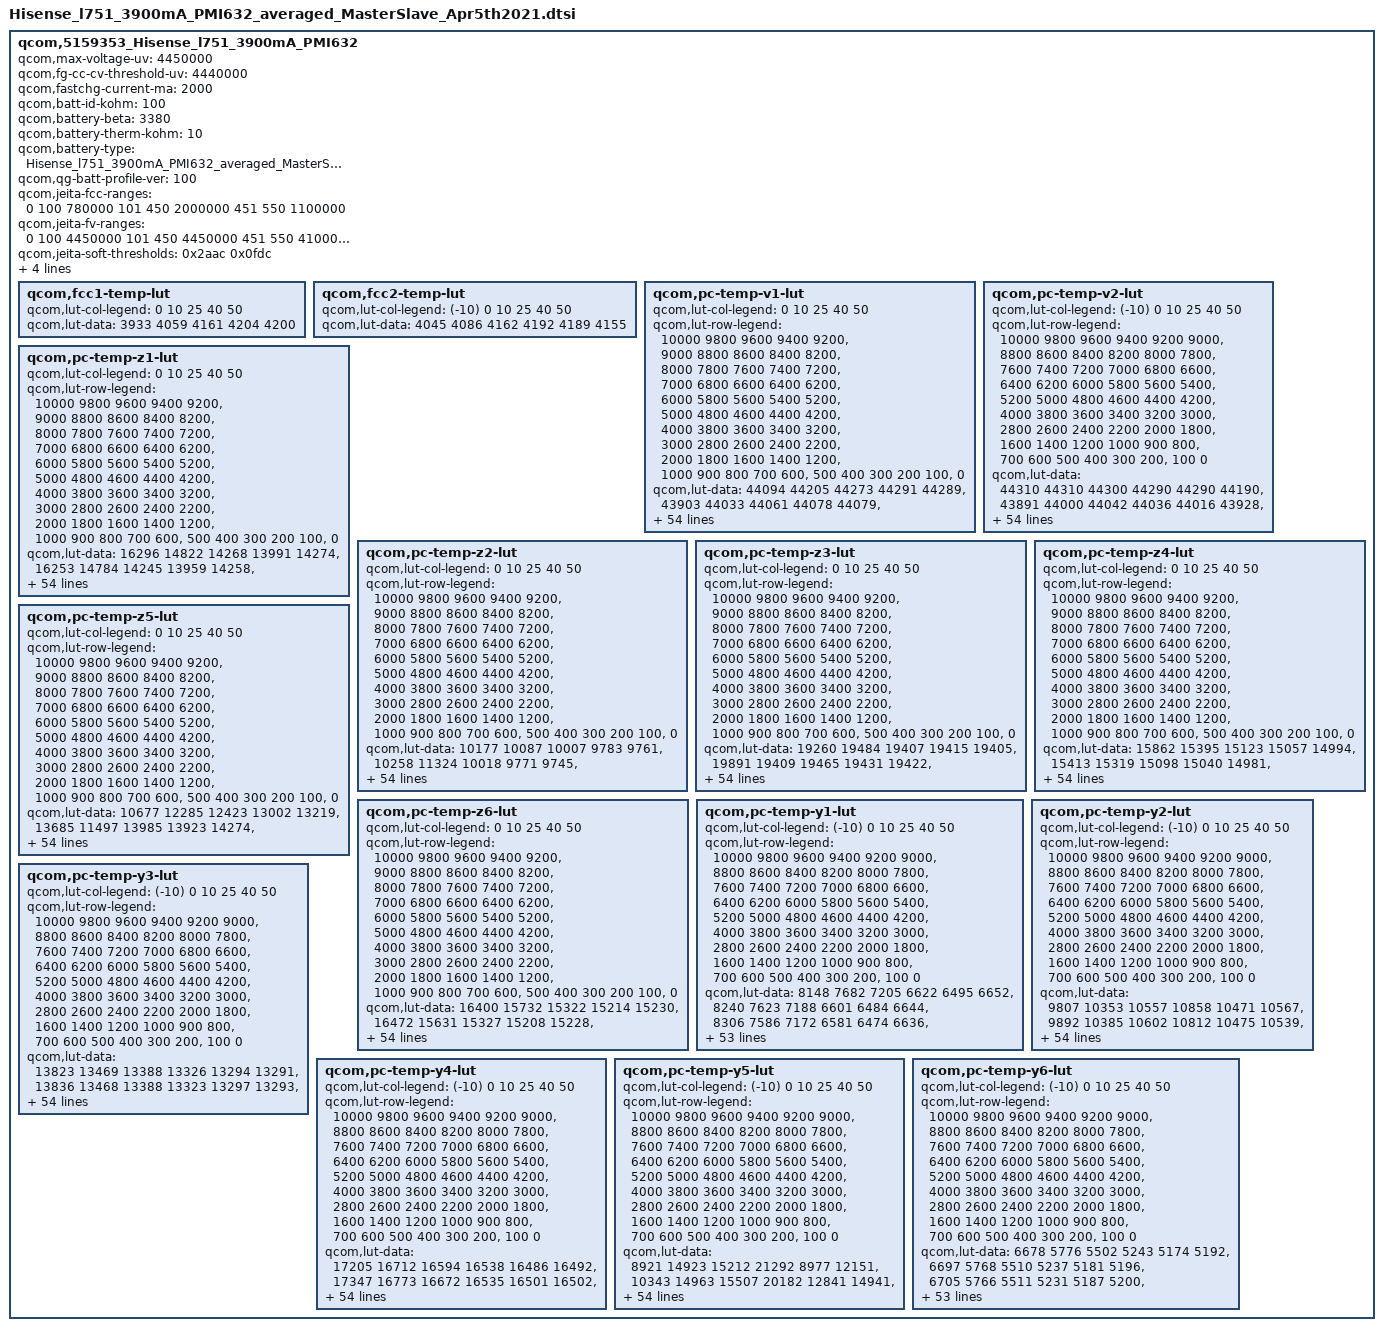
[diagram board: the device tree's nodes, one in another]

qcom,5159353_Hisense_l751_3900mA_PMI632 {
    /* 5159353_Hisense_l751_3900mA_PMI632_averaged_MasterSlave_Apr5th2021 */
    qcom,max-voltage-uv = <4450000>;
    qcom,fg-cc-cv-threshold-uv = <4440000>;
	qcom,fastchg-current-ma = <2000>;
	qcom,batt-id-kohm = <100>;
	qcom,battery-beta = <3380>;
	qcom,battery-therm-kohm = <10>;
    qcom,battery-type = "Hisense_l751_3900mA_PMI632_averaged_MasterSlave_Apr5th2021";
	qcom,qg-batt-profile-ver = <100>;

	qcom,jeita-fcc-ranges = <0  100  780000
				101 450  2000000
				451 550  1100000>;

	qcom,jeita-fv-ranges =  <0  100  4450000
				 101 450  4450000
				 451 550  4100000>;
	/* COOL = 10 DegC, WARM = 45 DegC */
	qcom,jeita-soft-thresholds = <0x2aac 0x0fdc>;
	/* COLD = 0 DegC, HOT = 53 DegC */
	qcom,jeita-hard-thresholds = <0x36b9 0x0ca0>;
	/* COOL hys = 13 degC, WARM hys = 42 degC */
	qcom,jeita-soft-hys-thresholds = <0x2767 0x1149>;
	qcom,jeita-soft-fcc-ua = <780000 1100000>;
	qcom,jeita-soft-fv-uv = <4450000 4100000>;

	qcom,fcc1-temp-lut {
		qcom,lut-col-legend = <0 10 25 40 50>;
		qcom,lut-data = <3933 4059 4161 4204 4200>;
	};

	qcom,fcc2-temp-lut {
		qcom,lut-col-legend = <(-10) 0 10 25 40 50>;
		qcom,lut-data = <4045 4086 4162 4192 4189 4155>;
	};

	qcom,pc-temp-v1-lut {
		qcom,lut-col-legend = <0 10 25 40 50>;
		qcom,lut-row-legend = <10000 9800 9600 9400 9200>,
			<9000 8800 8600 8400 8200>,
			<8000 7800 7600 7400 7200>,
			<7000 6800 6600 6400 6200>,
			<6000 5800 5600 5400 5200>,
			<5000 4800 4600 4400 4200>,
			<4000 3800 3600 3400 3200>,
			<3000 2800 2600 2400 2200>,
			<2000 1800 1600 1400 1200>,
			<1000 900 800 700 600>,
			<500 400 300 200 100>,
			<0>;
		qcom,lut-data = <44094 44205 44273 44291 44289>,
			<43903 44033 44061 44078 44079>,
			<43671 43842 43845 43865 43876>,
			<43436 43624 43630 43659 43668>,
			<43200 43391 43405 43437 43456>,
			<42959 43146 43172 43208 43228>,
			<42717 42888 42930 42973 42993>,
			<42473 42636 42677 42729 42749>,
			<42234 42388 42427 42481 42501>,
			<42000 42144 42177 42232 42256>,
			<41770 41906 41934 41982 42012>,
			<41545 41672 41700 41738 41770>,
			<41324 41443 41472 41497 41529>,
			<41111 41217 41244 41264 41293>,
			<40904 41002 41018 41040 41064>,
			<40701 40802 40802 40824 40841>,
			<40495 40605 40596 40612 40627>,
			<40291 40404 40397 40409 40422>,
			<40107 40202 40207 40223 40234>,
			<39940 40015 40020 40049 40058>,
			<39778 39853 39827 39862 39871>,
			<39616 39672 39630 39654 39668>,
			<39454 39412 39420 39438 39455>,
			<39270 39133 39174 39199 39211>,
			<39046 38951 38960 38972 38980>,
			<38849 38819 38825 38833 38840>,
			<38710 38711 38721 38738 38742>,
			<38597 38620 38621 38645 38644>,
			<38516 38541 38530 38552 38543>,
			<38455 38464 38444 38464 38448>,
			<38404 38393 38361 38385 38364>,
			<38354 38330 38286 38310 38287>,
			<38309 38275 38224 38242 38217>,
			<38270 38225 38168 38177 38152>,
			<38237 38181 38116 38114 38084>,
			<38205 38139 38067 38051 38011>,
			<38175 38099 38019 37988 37939>,
			<38143 38062 37975 37933 37875>,
			<38098 38014 37925 37873 37806>,
			<38032 37943 37852 37787 37713>,
			<37950 37851 37754 37674 37594>,
			<37833 37742 37642 37553 37469>,
			<37700 37609 37508 37426 37337>,
			<37578 37456 37355 37276 37185>,
			<37424 37298 37203 37126 37043>,
			<37274 37171 37104 37047 36974>,
			<37223 37135 37071 37010 36941>,
			<37177 37105 37045 36983 36917>,
			<37139 37078 37026 36960 36892>,
			<37105 37046 36992 36916 36842>,
			<37068 36999 36823 36710 36620>,
			<36985 36743 36420 36292 36194>,
			<36662 36289 35848 35730 35632>,
			<36106 35573 35063 34967 34866>,
			<35184 34476 33838 33810 33686>,
			<30000 30000 30000 30000 30000>;
	};

	qcom,pc-temp-v2-lut {
		qcom,lut-col-legend = <(-10) 0 10 25 40 50>;
		qcom,lut-row-legend = <10000 9800 9600 9400 9200 9000>,
			<8800 8600 8400 8200 8000 7800>,
			<7600 7400 7200 7000 6800 6600>,
			<6400 6200 6000 5800 5600 5400>,
			<5200 5000 4800 4600 4400 4200>,
			<4000 3800 3600 3400 3200 3000>,
			<2800 2600 2400 2200 2000 1800>,
			<1600 1400 1200 1000 900 800>,
			<700 600 500 400 300 200>,
			<100 0>;
		qcom,lut-data = <44310 44310 44300 44290 44290 44190>,
			<43891 44000 44042 44036 44016 43928>,
			<43526 43720 43802 43792 43759 43680>,
			<43226 43473 43585 43562 43528 43452>,
			<42978 43256 43387 43343 43314 43239>,
			<42728 43035 43172 43113 43086 43014>,
			<42460 42807 42933 42869 42838 42770>,
			<42191 42573 42688 42621 42586 42522>,
			<41923 42327 42442 42370 42336 42275>,
			<41659 42074 42193 42117 42086 42027>,
			<41453 41831 41949 41868 41837 41782>,
			<41306 41597 41708 41622 41591 41539>,
			<41151 41369 41470 41381 41350 41300>,
			<40944 41145 41232 41146 41115 41066>,
			<40698 40929 41002 40917 40887 40838>,
			<40401 40734 40785 40691 40665 40619>,
			<40027 40554 40574 40473 40450 40407>,
			<39709 40336 40359 40268 40246 40207>,
			<39489 40041 40141 40075 40052 40019>,
			<39293 39747 39911 39875 39861 39828>,
			<39064 39509 39654 39668 39677 39634>,
			<38821 39295 39406 39452 39478 39430>,
			<38626 39097 39188 39203 39226 39193>,
			<38470 38913 38989 38963 38973 38947>,
			<38349 38745 38816 38786 38795 38765>,
			<38267 38592 38664 38641 38653 38626>,
			<38204 38451 38528 38512 38526 38503>,
			<38144 38307 38406 38398 38411 38390>,
			<38089 38169 38295 38295 38307 38287>,
			<38035 38070 38189 38201 38214 38193>,
			<37982 38000 38091 38116 38130 38106>,
			<37928 37943 38005 38038 38056 38028>,
			<37873 37895 37928 37964 37990 37959>,
			<37816 37852 37864 37896 37919 37887>,
			<37758 37803 37814 37834 37842 37807>,
			<37698 37747 37769 37771 37759 37719>,
			<37635 37688 37721 37707 37666 37617>,
			<37568 37629 37671 37639 37570 37501>,
			<37498 37564 37610 37563 37484 37401>,
			<37424 37490 37536 37480 37400 37314>,
			<37344 37404 37444 37391 37310 37232>,
			<37255 37304 37328 37293 37219 37136>,
			<37158 37188 37189 37163 37102 36967>,
			<37059 37056 37051 37018 36950 36861>,
			<36957 36920 36920 36918 36863 36794>,
			<36854 36794 36845 36874 36831 36768>,
			<36807 36749 36804 36859 36819 36752>,
			<36765 36707 36779 36839 36802 36725>,
			<36729 36659 36718 36804 36760 36651>,
			<36690 36599 36641 36698 36622 36334>,
			<36655 36500 36404 36336 36232 35842>,
			<36592 36324 35945 35781 35676 35188>,
			<36461 35951 35247 35036 34939 34298>,
			<36163 35264 34331 34002 33943 33249>,
			<35495 34279 33175 32807 32804 32450>,
			<34477 33023 31869 28509 28709 29554>;
	};

	qcom,pc-temp-z1-lut {
		qcom,lut-col-legend = <0 10 25 40 50>;
		qcom,lut-row-legend = <10000 9800 9600 9400 9200>,
			<9000 8800 8600 8400 8200>,
			<8000 7800 7600 7400 7200>,
			<7000 6800 6600 6400 6200>,
			<6000 5800 5600 5400 5200>,
			<5000 4800 4600 4400 4200>,
			<4000 3800 3600 3400 3200>,
			<3000 2800 2600 2400 2200>,
			<2000 1800 1600 1400 1200>,
			<1000 900 800 700 600>,
			<500 400 300 200 100>,
			<0>;
		qcom,lut-data = <16296 14822 14268 13991 14274>,
			<16253 14784 14245 13959 14258>,
			<16252 14771 14224 13935 14239>,
			<16249 14751 14182 13917 14231>,
			<16223 14735 14154 13893 14224>,
			<16188 14710 14129 13876 14215>,
			<16164 14682 14104 13860 14209>,
			<16141 14657 14080 13845 14204>,
			<16117 14636 14064 13831 14201>,
			<16087 14616 14053 13821 14201>,
			<16069 14593 14044 13813 14201>,
			<16069 14571 14032 13809 14202>,
			<16069 14559 14021 13806 14206>,
			<16064 14550 14015 13804 14208>,
			<16011 14543 14010 13803 14209>,
			<15959 14535 14009 13802 14209>,
			<15943 14531 14009 13800 14211>,
			<15934 14538 14008 13799 14214>,
			<15930 14556 14006 13800 14216>,
			<15928 14560 14002 13802 14218>,
			<15927 14550 14001 13805 14220>,
			<15935 14544 14004 13807 14223>,
			<15953 14548 14008 13809 14225>,
			<15968 14557 14016 13812 14228>,
			<15979 14566 14023 13816 14233>,
			<15990 14577 14024 13820 14237>,
			<15999 14585 14025 13826 14243>,
			<16007 14590 14026 13832 14248>,
			<16021 14595 14028 13838 14253>,
			<16049 14603 14030 13843 14258>,
			<16072 14613 14037 13849 14263>,
			<16083 14628 14047 13856 14268>,
			<16091 14659 14061 13864 14275>,
			<16090 14678 14077 13874 14283>,
			<16075 14676 14085 13882 14292>,
			<16064 14672 14088 13889 14299>,
			<16074 14674 14093 13895 14307>,
			<16096 14687 14103 13903 14315>,
			<16119 14704 14114 13911 14321>,
			<16145 14724 14121 13918 14328>,
			<16171 14748 14128 13925 14333>,
			<16194 14781 14138 13934 14337>,
			<16220 14813 14155 13944 14341>,
			<16257 14805 14168 13953 14345>,
			<16282 14803 14179 13961 14348>,
			<16298 14837 14190 13965 14351>,
			<16304 14839 14194 13965 14351>,
			<16304 14854 14212 13969 14354>,
			<16301 14849 14214 13974 14360>,
			<16304 14862 14218 13984 14367>,
			<16342 14886 14237 14003 14378>,
			<16351 15046 14275 14014 14387>,
			<16378 15355 14309 14028 14399>,
			<16417 15325 14317 14052 14420>,
			<16417 15325 14317 14052 14420>,
			<16417 15325 14317 14052 14420>;
	};

	qcom,pc-temp-z2-lut {
		qcom,lut-col-legend = <0 10 25 40 50>;
		qcom,lut-row-legend = <10000 9800 9600 9400 9200>,
			<9000 8800 8600 8400 8200>,
			<8000 7800 7600 7400 7200>,
			<7000 6800 6600 6400 6200>,
			<6000 5800 5600 5400 5200>,
			<5000 4800 4600 4400 4200>,
			<4000 3800 3600 3400 3200>,
			<3000 2800 2600 2400 2200>,
			<2000 1800 1600 1400 1200>,
			<1000 900 800 700 600>,
			<500 400 300 200 100>,
			<0>;
		qcom,lut-data = <10177 10087 10007 9783 9761>,
			<10258 11324 10018 9771 9745>,
			<10036 11209 10047 9816 9751>,
			<9936 10961 10050 9778 9770>,
			<9918 10612 10032 9880 9832>,
			<9905 10316 10002 9879 9886>,
			<9892 10043 9983 9875 9901>,
			<9881 9968 9968 9847 9888>,
			<9875 9955 9953 9822 9873>,
			<9870 9947 9935 9818 9860>,
			<9868 9940 9926 9816 9851>,
			<9869 9935 10148 9820 9852>,
			<9872 9937 10481 9834 9859>,
			<9876 9947 10552 9838 9867>,
			<9885 9972 10572 9818 9880>,
			<9896 10136 10594 9801 9887>,
			<9905 10294 10625 9810 9885>,
			<9915 10229 10642 9824 9880>,
			<9930 10059 10397 9810 9856>,
			<9953 10011 10010 9753 9798>,
			<9973 10019 9961 9737 9784>,
			<9983 10028 9980 9808 9856>,
			<9989 10033 10000 9905 9952>,
			<9994 10037 10021 10011 10064>,
			<9996 10037 10033 10103 10160>,
			<9999 10031 10021 10086 10150>,
			<10005 10028 9997 9996 10080>,
			<10013 10027 9988 9954 10016>,
			<10017 10027 9984 9947 9961>,
			<10018 10028 9980 9938 9908>,
			<10020 10030 9977 9898 9852>,
			<10024 10032 9974 9842 9801>,
			<10030 10034 9970 9807 9759>,
			<10036 10037 9966 9780 9723>,
			<10042 10045 9968 9773 9715>,
			<10048 10057 9983 9778 9731>,
			<10056 10067 10001 9784 9754>,
			<10065 10077 10020 9793 9792>,
			<10077 10087 10038 9806 9835>,
			<10092 10102 10053 9841 9858>,
			<10106 10114 10065 9905 9872>,
			<10112 10115 10071 9926 9896>,
			<10137 10115 10074 9927 9939>,
			<17121 10121 10075 9934 9969>,
			<19781 10165 10078 9944 9977>,
			<19355 10238 10102 9853 9851>,
			<18978 10262 10105 9850 9844>,
			<19289 10315 10102 9852 9846>,
			<19818 10470 10101 9865 9863>,
			<20094 10287 10134 9894 9889>,
			<18666 11110 10142 9874 9863>,
			<18118 10773 10109 9794 9763>,
			<17012 10835 10062 9743 9708>,
			<14924 10113 10005 9709 9666>,
			<14924 10113 10005 9709 9666>,
			<14924 10113 10005 9709 9666>;
	};

	qcom,pc-temp-z3-lut {
		qcom,lut-col-legend = <0 10 25 40 50>;
		qcom,lut-row-legend = <10000 9800 9600 9400 9200>,
			<9000 8800 8600 8400 8200>,
			<8000 7800 7600 7400 7200>,
			<7000 6800 6600 6400 6200>,
			<6000 5800 5600 5400 5200>,
			<5000 4800 4600 4400 4200>,
			<4000 3800 3600 3400 3200>,
			<3000 2800 2600 2400 2200>,
			<2000 1800 1600 1400 1200>,
			<1000 900 800 700 600>,
			<500 400 300 200 100>,
			<0>;
		qcom,lut-data = <19260 19484 19407 19415 19405>,
			<19891 19409 19465 19431 19422>,
			<19848 19466 19493 19449 19416>,
			<19834 19545 19532 19447 19434>,
			<19853 19611 19535 19492 19462>,
			<19875 19647 19537 19499 19473>,
			<19885 19672 19543 19503 19482>,
			<19891 19682 19553 19506 19491>,
			<19892 19687 19555 19510 19495>,
			<19877 19689 19554 19514 19495>,
			<19860 19684 19552 19519 19495>,
			<19849 19674 19563 19518 19493>,
			<19841 19666 19579 19512 19489>,
			<19831 19657 19580 19506 19485>,
			<19819 19654 19574 19497 19481>,
			<19811 19671 19569 19490 19476>,
			<19811 19688 19565 19485 19472>,
			<19812 19676 19560 19481 19467>,
			<19809 19643 19538 19473 19458>,
			<19788 19632 19510 19460 19447>,
			<19771 19630 19508 19455 19443>,
			<19775 19629 19512 19461 19445>,
			<19786 19644 19517 19468 19447>,
			<19799 19668 19522 19481 19456>,
			<19819 19670 19524 19494 19469>,
			<19832 19662 19519 19493 19477>,
			<19831 19655 19509 19488 19482>,
			<19828 19649 19508 19488 19490>,
			<19824 19646 19512 19504 19505>,
			<19815 19647 19518 19515 19514>,
			<19805 19650 19529 19514 19507>,
			<19798 19651 19537 19510 19493>,
			<19791 19648 19534 19503 19479>,
			<19785 19645 19525 19493 19464>,
			<19778 19643 19519 19482 19451>,
			<19772 19642 19514 19471 19440>,
			<19767 19640 19509 19460 19430>,
			<19761 19637 19501 19446 19418>,
			<19753 19633 19494 19434 19408>,
			<19743 19627 19490 19435 19409>,
			<19734 19620 19487 19440 19414>,
			<19731 19612 19483 19442 19421>,
			<19725 19604 19478 19442 19429>,
			<19368 19594 19476 19446 19437>,
			<19256 19573 19474 19451 19441>,
			<19256 19546 19455 19423 19420>,
			<19256 19523 19450 19418 19414>,
			<19256 19498 19448 19411 19394>,
			<19256 19449 19432 19402 19382>,
			<19256 19497 19412 19390 19380>,
			<19256 19323 19440 19413 19398>,
			<19256 19316 19455 19446 19429>,
			<19256 19303 19465 19454 19435>,
			<19258 19547 19474 19459 19437>,
			<19258 19547 19474 19459 19437>,
			<19258 19547 19474 19459 19437>;
	};

	qcom,pc-temp-z4-lut {
		qcom,lut-col-legend = <0 10 25 40 50>;
		qcom,lut-row-legend = <10000 9800 9600 9400 9200>,
			<9000 8800 8600 8400 8200>,
			<8000 7800 7600 7400 7200>,
			<7000 6800 6600 6400 6200>,
			<6000 5800 5600 5400 5200>,
			<5000 4800 4600 4400 4200>,
			<4000 3800 3600 3400 3200>,
			<3000 2800 2600 2400 2200>,
			<2000 1800 1600 1400 1200>,
			<1000 900 800 700 600>,
			<500 400 300 200 100>,
			<0>;
		qcom,lut-data = <15862 15395 15123 15057 14994>,
			<15413 15319 15098 15040 14981>,
			<15622 15368 15019 14965 14923>,
			<15688 15277 15090 14921 14908>,
			<15563 15162 15050 15005 14976>,
			<15401 15102 14982 14965 14948>,
			<15296 15055 14936 14927 14923>,
			<15207 15009 14898 14899 14902>,
			<15140 14960 14867 14873 14883>,
			<15090 14921 14844 14846 14862>,
			<15049 14895 14818 14821 14841>,
			<15011 14874 14764 14804 14824>,
			<14978 14854 14709 14793 14808>,
			<14951 14836 14696 14785 14798>,
			<14928 14812 14690 14780 14793>,
			<14909 14762 14686 14775 14789>,
			<14890 14724 14680 14770 14785>,
			<14873 14740 14676 14765 14781>,
			<14863 14781 14695 14758 14773>,
			<14857 14792 14732 14751 14761>,
			<14850 14782 14754 14750 14758>,
			<14838 14774 14769 14770 14774>,
			<14823 14839 14796 14804 14801>,
			<14828 14941 14879 14869 14864>,
			<14890 14960 14941 14939 14932>,
			<14944 14961 14936 14941 14927>,
			<14958 14961 14921 14918 14885>,
			<14966 14940 14902 14891 14846>,
			<14965 14907 14871 14852 14809>,
			<14944 14884 14841 14819 14783>,
			<14920 14862 14813 14798 14772>,
			<14905 14845 14791 14783 14764>,
			<14890 14831 14778 14771 14754>,
			<14876 14819 14769 14761 14744>,
			<14862 14810 14766 14758 14739>,
			<14848 14803 14765 14757 14737>,
			<14835 14797 14764 14756 14736>,
			<14822 14792 14762 14756 14735>,
			<14811 14787 14761 14756 14734>,
			<14802 14784 14763 14762 14742>,
			<14793 14780 14768 14780 14765>,
			<14781 14773 14768 14784 14771>,
			<14775 14764 14761 14777 14763>,
			<15118 14754 14756 14775 14764>,
			<15166 14734 14746 14774 14768>,
			<15116 14709 14706 14725 14709>,
			<15111 14722 14699 14721 14704>,
			<15103 14737 14681 14709 14700>,
			<15097 14783 14679 14685 14679>,
			<15091 14717 14685 14668 14654>,
			<15085 14899 14676 14694 14699>,
			<15086 14988 14691 14718 14734>,
			<15111 14970 14695 14728 14752>,
			<15147 14742 14705 14738 14767>,
			<15147 14742 14705 14738 14767>,
			<15147 14742 14705 14738 14767>;
	};

	qcom,pc-temp-z5-lut {
		qcom,lut-col-legend = <0 10 25 40 50>;
		qcom,lut-row-legend = <10000 9800 9600 9400 9200>,
			<9000 8800 8600 8400 8200>,
			<8000 7800 7600 7400 7200>,
			<7000 6800 6600 6400 6200>,
			<6000 5800 5600 5400 5200>,
			<5000 4800 4600 4400 4200>,
			<4000 3800 3600 3400 3200>,
			<3000 2800 2600 2400 2200>,
			<2000 1800 1600 1400 1200>,
			<1000 900 800 700 600>,
			<500 400 300 200 100>,
			<0>;
		qcom,lut-data = <10677 12285 12423 13002 13219>,
			<13685 11497 13985 13923 14274>,
			<13815 11871 15523 15426 14573>,
			<14017 12580 16031 15776 16173>,
			<14353 13444 16119 16771 16612>,
			<14742 14434 16329 17236 17698>,
			<15223 15533 16790 17692 18732>,
			<15757 16432 17692 18143 19646>,
			<16030 17222 18393 18708 20456>,
			<16127 17747 18801 19806 21057>,
			<16228 17960 19401 21255 21612>,
			<16468 18127 21890 22444 22412>,
			<16847 18460 25242 23539 23459>,
			<17221 19057 26676 23861 24359>,
			<17555 20035 27475 23679 25071>,
			<17996 22930 28312 23530 25751>,
			<19110 25457 29417 24230 26629>,
			<20627 24675 30037 25350 27353>,
			<20968 22565 27677 25106 27224>,
			<20544 22043 23954 23731 26580>,
			<20206 22948 24126 23409 26475>,
			<21448 24531 26657 25827 27760>,
			<24714 29559 27603 27714 28705>,
			<28769 35876 26200 26906 27278>,
			<35271 35533 24103 25075 24631>,
			<39336 29690 21509 22728 22606>,
			<38353 25573 18941 19614 20777>,
			<36005 23852 18573 18747 20585>,
			<33758 22916 18676 19802 23475>,
			<31274 23107 18948 21103 25529>,
			<29459 23882 21222 22131 25521>,
			<28631 24657 23811 23059 25494>,
			<28080 25391 24787 23720 25037>,
			<27767 26274 25461 24234 23771>,
			<27543 27641 26607 24636 23339>,
			<27448 29238 28444 25005 23320>,
			<27628 30373 29214 25175 23288>,
			<27913 31320 28534 24108 22500>,
			<27935 31678 27552 22654 21489>,
			<27760 31261 26952 22986 21668>,
			<27648 30430 26424 24333 22602>,
			<28129 29196 25462 24501 23502>,
			<28562 27468 23847 22715 24319>,
			<15153 26094 23783 23223 26584>,
			<11036 26002 24542 25404 29304>,
			<11113 26250 23967 20658 23796>,
			<11067 20395 22424 19201 21181>,
			<11052 17027 23033 18650 17430>,
			<11038 14055 20197 19151 17735>,
			<11021 17894 17455 19376 21249>,
			<11018 11877 23338 23683 23807>,
			<11014 11415 21829 22565 21475>,
			<11004 11168 21977 20420 18281>,
			<10953 20548 21413 18452 15599>,
			<10953 20548 21413 18452 15599>,
			<10953 20548 21413 18452 15599>;
	};

	qcom,pc-temp-z6-lut {
		qcom,lut-col-legend = <0 10 25 40 50>;
		qcom,lut-row-legend = <10000 9800 9600 9400 9200>,
			<9000 8800 8600 8400 8200>,
			<8000 7800 7600 7400 7200>,
			<7000 6800 6600 6400 6200>,
			<6000 5800 5600 5400 5200>,
			<5000 4800 4600 4400 4200>,
			<4000 3800 3600 3400 3200>,
			<3000 2800 2600 2400 2200>,
			<2000 1800 1600 1400 1200>,
			<1000 900 800 700 600>,
			<500 400 300 200 100>,
			<0>;
		qcom,lut-data = <16400 15732 15322 15214 15230>,
			<16472 15631 15327 15208 15228>,
			<16462 15652 15297 15180 15197>,
			<16442 15628 15337 15156 15197>,
			<16357 15593 15314 15211 15238>,
			<16253 15567 15277 15195 15233>,
			<16182 15542 15255 15180 15227>,
			<16121 15514 15237 15168 15222>,
			<16067 15484 15221 15156 15217>,
			<16018 15456 15206 15146 15209>,
			<15975 15433 15191 15136 15200>,
			<15939 15413 15175 15127 15191>,
			<15908 15394 15160 15119 15183>,
			<15880 15378 15151 15111 15177>,
			<15854 15364 15145 15104 15172>,
			<15832 15350 15139 15098 15168>,
			<15815 15341 15133 15092 15164>,
			<15800 15339 15129 15087 15159>,
			<15787 15339 15127 15080 15151>,
			<15774 15338 15125 15070 15140>,
			<15767 15334 15127 15067 15137>,
			<15768 15332 15138 15079 15144>,
			<15774 15370 15155 15098 15158>,
			<15786 15428 15194 15134 15192>,
			<15825 15438 15223 15172 15229>,
			<15857 15438 15219 15173 15229>,
			<15866 15438 15209 15161 15216>,
			<15872 15428 15200 15151 15206>,
			<15871 15414 15190 15144 15200>,
			<15861 15407 15182 15137 15193>,
			<15849 15403 15177 15129 15185>,
			<15842 15398 15173 15121 15176>,
			<15835 15393 15167 15113 15165>,
			<15830 15389 15161 15105 15154>,
			<15826 15388 15158 15099 15145>,
			<15824 15387 15157 15093 15139>,
			<15822 15387 15155 15088 15134>,
			<15822 15387 15152 15081 15128>,
			<15822 15387 15149 15075 15122>,
			<15826 15387 15150 15079 15126>,
			<15831 15388 15152 15090 15139>,
			<15840 15388 15152 15093 15145>,
			<15846 15387 15149 15092 15147>,
			<15843 15384 15149 15094 15152>,
			<15825 15377 15148 15098 15157>,
			<15817 15360 15125 15063 15120>,
			<15818 15356 15121 15059 15115>,
			<15815 15357 15115 15050 15104>,
			<15814 15357 15106 15036 15089>,
			<15817 15352 15104 15025 15078>,
			<15822 15349 15118 15050 15107>,
			<15839 15441 15141 15082 15143>,
			<15864 15460 15155 15094 15157>,
			<15905 15494 15174 15107 15170>,
			<15905 15494 15174 15107 15170>,
			<15905 15494 15174 15107 15170>;
	};

	qcom,pc-temp-y1-lut {
		qcom,lut-col-legend = <(-10) 0 10 25 40 50>;
		qcom,lut-row-legend = <10000 9800 9600 9400 9200 9000>,
			<8800 8600 8400 8200 8000 7800>,
			<7600 7400 7200 7000 6800 6600>,
			<6400 6200 6000 5800 5600 5400>,
			<5200 5000 4800 4600 4400 4200>,
			<4000 3800 3600 3400 3200 3000>,
			<2800 2600 2400 2200 2000 1800>,
			<1600 1400 1200 1000 900 800>,
			<700 600 500 400 300 200>,
			<100 0>;
		qcom,lut-data = <8148 7682 7205 6622 6495 6652>,
			<8240 7623 7188 6601 6484 6644>,
			<8306 7586 7172 6581 6474 6636>,
			<8349 7565 7157 6563 6464 6627>,
			<8371 7556 7145 6547 6455 6621>,
			<8375 7556 7135 6535 6447 6617>,
			<8346 7577 7127 6526 6440 6616>,
			<8314 7597 7121 6517 6433 6614>,
			<8315 7591 7117 6504 6425 6611>,
			<8321 7577 7113 6489 6418 6609>,
			<8321 7577 7107 6479 6409 6607>,
			<8303 7595 7099 6471 6399 6605>,
			<8289 7605 7098 6464 6394 6605>,
			<8295 7596 7112 6459 6391 6607>,
			<8306 7585 7124 6455 6389 6610>,
			<8313 7589 7111 6453 6383 6610>,
			<8317 7608 7088 6452 6376 6611>,
			<8321 7614 7089 6451 6375 6611>,
			<8325 7608 7102 6450 6374 6612>,
			<8329 7600 7107 6450 6374 6613>,
			<8336 7593 7097 6457 6374 6614>,
			<8346 7587 7089 6463 6373 6617>,
			<8362 7590 7098 6464 6375 6674>,
			<8393 7611 7116 6466 6377 6777>,
			<8415 7623 7116 6469 6381 6785>,
			<8416 7625 7105 6475 6388 6729>,
			<8415 7626 7100 6481 6392 6700>,
			<8407 7622 7100 6486 6394 6701>,
			<8371 7613 7101 6492 6396 6703>,
			<8350 7610 7103 6499 6402 6706>,
			<8382 7620 7106 6507 6411 6710>,
			<8425 7628 7107 6512 6418 6714>,
			<8415 7621 7107 6515 6424 6719>,
			<8364 7609 7109 6522 6428 6723>,
			<8344 7612 7120 6536 6431 6725>,
			<8372 7633 7130 6544 6434 6728>,
			<8399 7642 7126 6543 6436 6730>,
			<8385 7632 7117 6541 6439 6733>,
			<8352 7618 7116 6541 6440 6735>,
			<8343 7607 7118 6542 6441 6736>,
			<8347 7600 7122 6545 6443 6738>,
			<8352 7619 7126 6548 6445 6741>,
			<8363 7622 7132 6569 6449 6745>,
			<8412 7644 7145 6563 6454 6751>,
			<8500 7643 7148 6572 6463 6756>,
			<8458 7648 7153 6589 6466 6629>,
			<8465 7653 7153 6590 6463 6628>,
			<8480 7674 7157 6589 6466 6623>,
			<8567 7687 7198 6591 6467 6620>,
			<8548 7681 7167 6594 6466 6622>,
			<8507 7689 7178 6603 6470 6627>,
			<8548 7704 7213 6623 6485 6640>,
			<8606 7778 7232 6660 6499 6652>,
			<8736 7891 7448 6727 6527 6736>,
			<8736 7891 7448 6727 6527 6736>,
			<8736 7891 7448 6727 6527 6736>;
	};

	qcom,pc-temp-y2-lut {
		qcom,lut-col-legend = <(-10) 0 10 25 40 50>;
		qcom,lut-row-legend = <10000 9800 9600 9400 9200 9000>,
			<8800 8600 8400 8200 8000 7800>,
			<7600 7400 7200 7000 6800 6600>,
			<6400 6200 6000 5800 5600 5400>,
			<5200 5000 4800 4600 4400 4200>,
			<4000 3800 3600 3400 3200 3000>,
			<2800 2600 2400 2200 2000 1800>,
			<1600 1400 1200 1000 900 800>,
			<700 600 500 400 300 200>,
			<100 0>;
		qcom,lut-data = <9807 10353 10557 10858 10471 10567>,
			<9892 10385 10602 10812 10475 10539>,
			<9973 10429 10628 10767 10477 10513>,
			<10048 10472 10640 10727 10476 10488>,
			<10113 10504 10644 10692 10474 10465>,
			<10165 10513 10642 10664 10468 10443>,
			<10199 10506 10621 10642 10439 10421>,
			<10236 10500 10599 10624 10409 10405>,
			<10322 10503 10591 10612 10390 10401>,
			<10445 10512 10585 10601 10375 10398>,
			<10477 10517 10585 10588 10366 10389>,
			<10444 10519 10587 10573 10359 10374>,
			<10419 10523 10591 10571 10358 10364>,
			<10459 10579 10605 10578 10360 10359>,
			<10527 10655 10627 10588 10361 10357>,
			<10435 10676 10658 10595 10361 10364>,
			<9941 10684 10696 10605 10360 10381>,
			<9674 10696 10733 10630 10372 10402>,
			<9672 10715 10769 10677 10421 10431>,
			<9671 10735 10783 10721 10487 10473>,
			<9669 10750 10784 10769 10605 10567>,
			<9667 10764 10785 10791 10671 10640>,
			<9665 10779 10797 10776 10605 10608>,
			<9664 10794 10819 10756 10519 10545>,
			<9663 10801 10837 10760 10528 10535>,
			<9662 10792 10853 10779 10573 10550>,
			<9662 10781 10866 10797 10585 10567>,
			<9661 10776 10874 10816 10578 10581>,
			<9661 10773 10882 10833 10574 10596>,
			<9660 10767 10890 10851 10595 10609>,
			<9660 10755 10897 10864 10630 10622>,
			<9659 10736 10897 10869 10655 10655>,
			<9659 10706 10889 10871 10677 10737>,
			<9659 10653 10879 10871 10681 10778>,
			<9659 10475 10872 10867 10672 10745>,
			<9659 9997 10863 10862 10660 10693>,
			<9658 9747 10847 10859 10639 10646>,
			<9658 9709 10823 10856 10620 10601>,
			<9658 9690 10794 10848 10618 10592>,
			<9658 9680 10755 10835 10619 10598>,
			<9658 9674 10715 10823 10619 10599>,
			<9657 9670 10668 10819 10646 10596>,
			<9657 9666 10630 10825 10597 10546>,
			<9657 9666 10592 10789 10588 10499>,
			<9657 9663 10522 10783 10508 10421>,
			<9656 9660 10446 10736 10493 10394>,
			<9656 9660 10402 10723 10499 10427>,
			<9655 9659 10348 10726 10530 10451>,
			<9655 9658 10287 10734 10541 10450>,
			<9654 9656 10172 10727 10525 10383>,
			<9653 9655 9747 10675 10449 10336>,
			<9651 9653 9676 10607 10396 10264>,
			<9649 9651 9655 10517 10326 10213>,
			<9648 9650 9651 10341 10316 9977>,
			<9648 9650 9651 10341 10316 9977>,
			<9648 9650 9651 10341 10316 9977>;
	};

	qcom,pc-temp-y3-lut {
		qcom,lut-col-legend = <(-10) 0 10 25 40 50>;
		qcom,lut-row-legend = <10000 9800 9600 9400 9200 9000>,
			<8800 8600 8400 8200 8000 7800>,
			<7600 7400 7200 7000 6800 6600>,
			<6400 6200 6000 5800 5600 5400>,
			<5200 5000 4800 4600 4400 4200>,
			<4000 3800 3600 3400 3200 3000>,
			<2800 2600 2400 2200 2000 1800>,
			<1600 1400 1200 1000 900 800>,
			<700 600 500 400 300 200>,
			<100 0>;
		qcom,lut-data = <13823 13469 13388 13326 13294 13291>,
			<13836 13468 13388 13323 13297 13293>,
			<13838 13469 13388 13321 13301 13296>,
			<13832 13470 13388 13320 13306 13300>,
			<13821 13473 13388 13319 13310 13303>,
			<13805 13476 13388 13319 13310 13304>,
			<13781 13481 13387 13320 13310 13303>,
			<13754 13485 13386 13321 13310 13303>,
			<13728 13482 13386 13321 13310 13304>,
			<13701 13476 13386 13321 13311 13306>,
			<13667 13471 13387 13322 13311 13307>,
			<13616 13467 13388 13323 13312 13307>,
			<13582 13462 13389 13325 13312 13308>,
			<13577 13451 13384 13329 13314 13308>,
			<13575 13442 13379 13331 13315 13308>,
			<13578 13439 13375 13329 13314 13308>,
			<13596 13438 13373 13326 13314 13310>,
			<13605 13436 13373 13327 13315 13312>,
			<13603 13427 13373 13329 13316 13315>,
			<13597 13416 13373 13329 13317 13316>,
			<13588 13408 13366 13328 13319 13315>,
			<13572 13401 13358 13327 13320 13312>,
			<13561 13395 13354 13322 13313 13306>,
			<13554 13390 13350 13316 13303 13298>,
			<13550 13385 13347 13314 13302 13296>,
			<13571 13379 13343 13312 13301 13296>,
			<13621 13373 13341 13311 13301 13296>,
			<13666 13368 13340 13310 13298 13296>,
			<13708 13364 13339 13309 13297 13296>,
			<13752 13359 13337 13310 13295 13294>,
			<13800 13353 13335 13310 13294 13291>,
			<13852 13350 13335 13310 13295 13291>,
			<13902 13354 13335 13309 13298 13295>,
			<13953 13362 13336 13309 13298 13297>,
			<14006 13369 13337 13309 13299 13298>,
			<14061 13376 13338 13309 13299 13299>,
			<14117 13386 13339 13310 13299 13298>,
			<14172 13407 13342 13311 13299 13298>,
			<14225 13434 13344 13311 13300 13298>,
			<14274 13460 13348 13311 13302 13301>,
			<14316 13490 13351 13312 13303 13302>,
			<14354 13528 13352 13313 13303 13301>,
			<14391 13573 13347 13308 13300 13295>,
			<14443 13565 13348 13303 13295 13295>,
			<14485 13628 13349 13308 13299 13302>,
			<14617 13737 13365 13316 13310 13309>,
			<14699 13814 13370 13321 13315 13312>,
			<14800 13904 13385 13326 13319 13314>,
			<14944 14030 13394 13331 13319 13315>,
			<15141 14197 13422 13331 13315 13307>,
			<15488 14459 13474 13325 13312 13311>,
			<16437 14896 13635 13333 13315 13319>,
			<19652 16155 14529 13350 13329 13341>,
			<29801 23362 24523 13420 13359 14592>,
			<29801 23362 24523 13420 13359 14592>,
			<29801 23362 24523 13420 13359 14592>;
	};

	qcom,pc-temp-y4-lut {
		qcom,lut-col-legend = <(-10) 0 10 25 40 50>;
		qcom,lut-row-legend = <10000 9800 9600 9400 9200 9000>,
			<8800 8600 8400 8200 8000 7800>,
			<7600 7400 7200 7000 6800 6600>,
			<6400 6200 6000 5800 5600 5400>,
			<5200 5000 4800 4600 4400 4200>,
			<4000 3800 3600 3400 3200 3000>,
			<2800 2600 2400 2200 2000 1800>,
			<1600 1400 1200 1000 900 800>,
			<700 600 500 400 300 200>,
			<100 0>;
		qcom,lut-data = <17205 16712 16594 16538 16486 16492>,
			<17347 16773 16672 16535 16501 16502>,
			<17484 16866 16735 16532 16511 16511>,
			<17599 16964 16781 16529 16516 16518>,
			<17675 17041 16808 16527 16518 16522>,
			<17696 17072 16811 16525 16518 16523>,
			<17666 17082 16790 16523 16512 16520>,
			<17622 17086 16764 16522 16508 16517>,
			<17584 17071 16747 16523 16510 16516>,
			<17548 17038 16733 16527 16513 16515>,
			<17556 17031 16727 16532 16515 16515>,
			<17707 17039 16723 16537 16517 16517>,
			<17824 17051 16723 16543 16520 16519>,
			<17771 17080 16737 16548 16524 16522>,
			<17646 17118 16760 16555 16530 16525>,
			<17514 17147 16799 16574 16538 16529>,
			<17353 17173 16840 16601 16547 16534>,
			<17228 17172 16844 16634 16561 16541>,
			<17158 17051 16834 16670 16580 16553>,
			<17096 16918 16817 16680 16602 16569>,
			<17005 16863 16759 16679 16632 16597>,
			<16894 16825 16693 16677 16647 16617>,
			<16845 16788 16647 16615 16598 16587>,
			<16832 16754 16610 16532 16528 16526>,
			<16822 16724 16591 16512 16511 16507>,
			<16811 16698 16580 16502 16504 16501>,
			<16801 16672 16573 16501 16503 16500>,
			<16799 16630 16569 16505 16508 16503>,
			<16802 16579 16565 16510 16515 16509>,
			<16806 16566 16559 16516 16526 16519>,
			<16812 16582 16550 16522 16540 16533>,
			<16819 16601 16542 16529 16553 16546>,
			<16826 16612 16534 16536 16566 16559>,
			<16833 16623 16531 16540 16569 16567>,
			<16841 16647 16541 16542 16567 16573>,
			<16850 16697 16558 16543 16564 16576>,
			<16858 16735 16578 16539 16546 16565>,
			<16865 16756 16601 16535 16527 16537>,
			<16871 16773 16618 16534 16527 16531>,
			<16875 16786 16632 16534 16533 16543>,
			<16877 16796 16634 16538 16540 16564>,
			<16876 16797 16632 16539 16550 16580>,
			<16865 16793 16596 16506 16520 16497>,
			<16850 16743 16578 16491 16477 16471>,
			<16830 16742 16590 16491 16474 16492>,
			<16835 16763 16628 16521 16534 16601>,
			<16847 16783 16649 16553 16596 16659>,
			<16859 16813 16695 16599 16653 16708>,
			<16866 16859 16745 16663 16699 16723>,
			<16893 16930 16827 16684 16675 16584>,
			<16912 17025 16895 16590 16565 16561>,
			<17037 17110 16969 16597 16567 16564>,
			<17669 17409 17384 16654 16584 16581>,
			<20688 21998 27163 16862 16706 19092>,
			<20688 21998 27163 16862 16706 19092>,
			<20688 21998 27163 16862 16706 19092>;
	};

	qcom,pc-temp-y5-lut {
		qcom,lut-col-legend = <(-10) 0 10 25 40 50>;
		qcom,lut-row-legend = <10000 9800 9600 9400 9200 9000>,
			<8800 8600 8400 8200 8000 7800>,
			<7600 7400 7200 7000 6800 6600>,
			<6400 6200 6000 5800 5600 5400>,
			<5200 5000 4800 4600 4400 4200>,
			<4000 3800 3600 3400 3200 3000>,
			<2800 2600 2400 2200 2000 1800>,
			<1600 1400 1200 1000 900 800>,
			<700 600 500 400 300 200>,
			<100 0>;
		qcom,lut-data = <8921 14923 15212 21292 8977 12151>,
			<10343 14963 15507 20182 12841 14941>,
			<11904 15040 15757 18839 15888 16954>,
			<13397 15150 15946 17527 18048 18261>,
			<14616 15285 16058 16511 19250 18932>,
			<15361 15445 16076 16025 19364 18979>,
			<15835 15693 16006 15827 18161 18004>,
			<16108 15867 15902 15620 17003 17190>,
			<16154 15793 15782 15222 16563 17121>,
			<16172 15589 15638 14781 16211 17079>,
			<16214 15423 15506 14467 15647 16904>,
			<16338 15293 15381 14211 14945 16432>,
			<16573 15128 15158 14175 14618 15926>,
			<18181 14774 14540 14391 14520 15361>,
			<20600 14444 14101 14534 14398 14903>,
			<20319 15215 14156 13912 14028 14646>,
			<16942 17681 14333 13097 13574 14475>,
			<15133 18581 15076 13151 13309 14458>,
			<16032 18440 17273 13655 13114 14485>,
			<17099 18320 18635 14599 13232 14562>,
			<16797 18526 19167 17118 14746 15284>,
			<15412 19000 19496 19021 16273 16282>,
			<14016 19383 19714 19685 17129 17189>,
			<12425 19721 19858 20044 17760 17999>,
			<11432 20014 19789 19922 18134 18076>,
			<11533 20310 19415 19451 18399 17720>,
			<11804 20509 19258 18977 18257 17230>,
			<11987 19959 19503 18428 16576 16483>,
			<12112 18183 19803 18167 15216 15635>,
			<12219 16602 19944 18600 14812 14835>,
			<12314 15050 20050 19216 14596 14119>,
			<12398 14217 20180 19433 14969 14209>,
			<12477 14676 20339 19553 16204 15673>,
			<12549 15417 20387 19746 17246 17265>,
			<12615 15177 19934 20069 18144 18850>,
			<12672 13701 19344 20382 18754 19967>,
			<12730 13006 18998 20681 19066 19978>,
			<12811 13100 18740 20885 19276 19871>,
			<12896 13230 18729 20518 19439 19923>,
			<12915 13320 18869 19734 19539 20382>,
			<12902 13379 18851 19481 18960 20439>,
			<12853 13372 18499 19867 19285 20376>,
			<12687 13318 17532 20670 21392 20005>,
			<12479 12846 17727 17322 18599 19107>,
			<12053 12858 16532 18465 16747 16439>,
			<11981 12673 17937 17791 15903 13985>,
			<11893 12880 16798 17379 15039 13574>,
			<11884 12930 17263 16957 14739 13526>,
			<12070 12908 16015 16649 14455 13622>,
			<12069 12930 16188 16592 14152 13662>,
			<12401 12935 14493 16890 14851 13996>,
			<12046 13089 13491 17812 14538 13967>,
			<10708 12019 11837 18384 15538 18192>,
			<9547 9758 9823 19055 20814 20370>,
			<9547 9758 9823 19055 20814 20370>,
			<9547 9758 9823 19055 20814 20370>;
	};

	qcom,pc-temp-y6-lut {
		qcom,lut-col-legend = <(-10) 0 10 25 40 50>;
		qcom,lut-row-legend = <10000 9800 9600 9400 9200 9000>,
			<8800 8600 8400 8200 8000 7800>,
			<7600 7400 7200 7000 6800 6600>,
			<6400 6200 6000 5800 5600 5400>,
			<5200 5000 4800 4600 4400 4200>,
			<4000 3800 3600 3400 3200 3000>,
			<2800 2600 2400 2200 2000 1800>,
			<1600 1400 1200 1000 900 800>,
			<700 600 500 400 300 200>,
			<100 0>;
		qcom,lut-data = <6678 5776 5502 5243 5174 5192>,
			<6697 5768 5510 5237 5181 5196>,
			<6705 5766 5511 5231 5187 5200>,
			<6704 5767 5508 5225 5191 5204>,
			<6697 5771 5501 5220 5193 5207>,
			<6686 5777 5492 5217 5193 5207>,
			<6654 5789 5478 5215 5190 5206>,
			<6611 5798 5464 5213 5188 5205>,
			<6572 5786 5453 5212 5189 5206>,
			<6535 5757 5444 5211 5189 5207>,
			<6526 5743 5437 5211 5189 5207>,
			<6530 5736 5431 5213 5189 5208>,
			<6534 5732 5429 5215 5189 5209>,
			<6522 5732 5427 5218 5192 5210>,
			<6492 5731 5427 5222 5194 5212>,
			<6449 5734 5432 5226 5196 5213>,
			<6374 5743 5440 5231 5198 5215>,
			<6323 5744 5441 5239 5201 5219>,
			<6306 5705 5438 5251 5208 5224>,
			<6292 5661 5432 5254 5215 5230>,
			<6269 5642 5411 5253 5224 5236>,
			<6239 5628 5386 5251 5228 5240>,
			<6230 5617 5370 5230 5209 5235>,
			<6232 5607 5357 5203 5181 5222>,
			<6237 5600 5352 5196 5176 5213>,
			<6255 5596 5348 5193 5174 5205>,
			<6292 5592 5347 5192 5174 5203>,
			<6327 5586 5347 5193 5174 5204>,
			<6363 5578 5347 5195 5175 5205>,
			<6401 5578 5347 5198 5177 5207>,
			<6440 5591 5346 5201 5182 5209>,
			<6481 5611 5346 5204 5187 5213>,
			<6523 5634 5348 5207 5193 5220>,
			<6566 5661 5351 5209 5194 5224>,
			<6610 5691 5359 5211 5194 5227>,
			<6655 5723 5371 5212 5194 5228>,
			<6699 5759 5384 5212 5190 5225>,
			<6742 5801 5398 5212 5184 5217>,
			<6784 5846 5414 5213 5185 5216>,
			<6821 5894 5431 5213 5188 5222>,
			<6854 5945 5448 5216 5191 5229>,
			<6888 5998 5460 5218 5195 5233>,
			<6924 6052 5451 5207 5184 5205>,
			<6972 6050 5454 5200 5169 5199>,
			<7018 6116 5478 5207 5173 5212>,
			<7124 6224 5538 5225 5199 5234>,
			<7196 6300 5562 5239 5220 5253>,
			<7284 6389 5612 5256 5239 5268>,
			<7403 6509 5660 5278 5252 5272>,
			<7573 6678 5743 5284 5243 5227>,
			<7874 6921 5830 5256 5209 5224>,
			<8679 7305 6038 5271 5214 5233>,
			<11351 8399 6968 5317 5231 5257>,
			<19461 15081 17151 5474 5293 6934>,
			<19461 15081 17151 5474 5293 6934>,
			<19461 15081 17151 5474 5293 6934>;
	};

};
